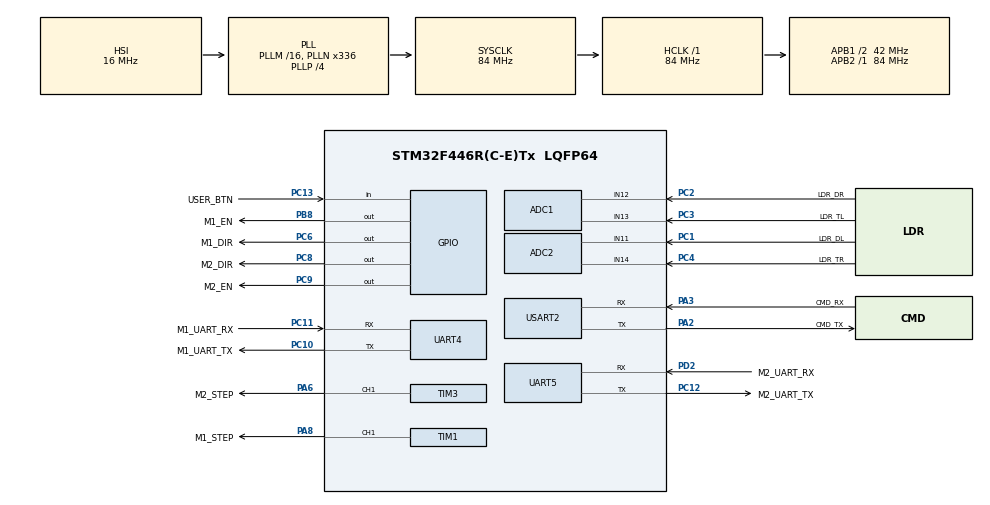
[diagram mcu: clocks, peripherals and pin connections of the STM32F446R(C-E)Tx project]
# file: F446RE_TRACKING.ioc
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ADC1.Channel-0\#ChannelRegularConversion=ADC_CHANNEL_12
ADC1.Channel-1\#ChannelRegularConversion=ADC_CHANNEL_13
ADC1.Channel-2\#ChannelRegularConversion=ADC_CHANNEL_12
ADC1.ContinuousConvMode=ENABLE
ADC1.DMAContinuousRequests=ENABLE
ADC1.EOCSelection=ADC_EOC_SEQ_CONV
ADC1.NbrOfConversion=2
ADC1.NbrOfConversionFlag=2
ADC1.Rank-0\#ChannelRegularConversion=2
ADC1.Rank-1\#ChannelRegularConversion=1
ADC1.Rank-2\#ChannelRegularConversion=2
ADC1.SamplingTime-0\#ChannelRegularConversion=ADC_SAMPLETIME_28CYCLES
ADC1.SamplingTime-1\#ChannelRegularConversion=ADC_SAMPLETIME_28CYCLES
ADC1.SamplingTime-2\#ChannelRegularConversion=ADC_SAMPLETIME_28CYCLES
ADC1.ScanConvMode=ENABLE
ADC1.master=1
ADC2.Channel-0\#ChannelRegularConversion=ADC_CHANNEL_14
ADC2.Channel-1\#ChannelRegularConversion=ADC_CHANNEL_11
ADC2.Channel-3\#ChannelRegularConversion=ADC_CHANNEL_11
ADC2.ContinuousConvMode=ENABLE
ADC2.DMAContinuousRequests=ENABLE
ADC2.EOCSelection=ADC_EOC_SEQ_CONV
ADC2.NbrOfConversion=2
ADC2.NbrOfConversionFlag=2
ADC2.Rank-0\#ChannelRegularConversion=1
ADC2.Rank-1\#ChannelRegularConversion=2
ADC2.Rank-3\#ChannelRegularConversion=2
ADC2.SamplingTime-0\#ChannelRegularConversion=ADC_SAMPLETIME_28CYCLES
ADC2.SamplingTime-1\#ChannelRegularConversion=ADC_SAMPLETIME_28CYCLES
ADC2.SamplingTime-3\#ChannelRegularConversion=ADC_SAMPLETIME_28CYCLES
Dma.ADC1.0.Direction=DMA_PERIPH_TO_MEMORY
Dma.ADC1.0.FIFOMode=DMA_FIFOMODE_DISABLE
Dma.ADC1.0.Instance=DMA2_Stream0
Dma.ADC1.0.MemDataAlignment=DMA_MDATAALIGN_HALFWORD
Dma.ADC1.0.MemInc=DMA_MINC_ENABLE
Dma.ADC1.0.Mode=DMA_CIRCULAR
Dma.ADC1.0.PeriphDataAlignment=DMA_PDATAALIGN_HALFWORD
Dma.ADC1.0.PeriphInc=DMA_PINC_DISABLE
Dma.ADC1.0.Priority=DMA_PRIORITY_LOW
Dma.ADC2.1.Direction=DMA_PERIPH_TO_MEMORY
Dma.ADC2.1.FIFOMode=DMA_FIFOMODE_DISABLE
Dma.ADC2.1.Instance=DMA2_Stream3
Dma.ADC2.1.MemDataAlignment=DMA_MDATAALIGN_HALFWORD
Dma.ADC2.1.MemInc=DMA_MINC_ENABLE
Dma.ADC2.1.Mode=DMA_CIRCULAR
Dma.ADC2.1.PeriphDataAlignment=DMA_PDATAALIGN_HALFWORD
Dma.ADC2.1.PeriphInc=DMA_PINC_DISABLE
Dma.ADC2.1.Priority=DMA_PRIORITY_LOW
Dma.Request0=ADC1
Dma.Request1=ADC2
Mcu.Family=STM32F4
Mcu.Name=STM32F446R(C-E)Tx
Mcu.Package=LQFP64
NVIC.ADC_IRQn=true\:0\:0\:false\:false\:true\:true\:true\:true
NVIC.DMA2_Stream0_IRQn=true\:0\:0\:false\:false\:true\:false\:true\:true
NVIC.DMA2_Stream3_IRQn=true\:0\:0\:false\:false\:true\:false\:true\:true
NVIC.PriorityGroup=NVIC_PRIORITYGROUP_0
NVIC.UART4_IRQn=true\:0\:0\:false\:false\:true\:true\:true\:true
NVIC.UART5_IRQn=true\:0\:0\:false\:false\:true\:true\:true\:true
PA13.GPIO_Label=TMS
PA13.Mode=Serial_Wire
PA13.Signal=SYS_JTMS-SWDIO
PA14.GPIO_Label=TCK
PA14.Mode=Serial_Wire
PA14.Signal=SYS_JTCK-SWCLK
PA2.GPIO_Label=CMD_TX
PA2.Mode=Asynchronous
PA2.Signal=USART2_TX
PA3.GPIO_Label=CMD_RX
PA3.Mode=Asynchronous
PA3.Signal=USART2_RX
PA6.GPIO_Label=M2_STEP
PA6.Signal=S_TIM3_CH1
PA8.GPIO_Label=M1_STEP
PA8.Signal=S_TIM1_CH1
PB3.GPIO_Label=SWO
PB3.Signal=SYS_JTDO-SWO
PB8.GPIO_Label=M1_EN
PB8.Signal=GPIO_Output
PC1.GPIO_Label=LDR_DL
PC1.Signal=ADCx_IN11
PC10.GPIO_Label=M1_UART_TX
PC10.Mode=Asynchronous
PC10.Signal=UART4_TX
PC11.GPIO_Label=M1_UART_RX
PC11.Mode=Asynchronous
PC11.Signal=UART4_RX
PC12.GPIO_Label=M2_UART_TX
PC12.Mode=Asynchronous
PC12.Signal=UART5_TX
PC13.GPIO_Label=USER_BTN
PC13.GPIO_PuPd=GPIO_PULLUP
PC13.Signal=GPIO_Input
PC14-OSC32_IN.Mode=LSE-External-Oscillator
PC14-OSC32_IN.Signal=RCC_OSC32_IN
PC15-OSC32_OUT.Mode=LSE-External-Oscillator
PC15-OSC32_OUT.Signal=RCC_OSC32_OUT
PC2.GPIO_Label=LDR_DR
PC2.Signal=ADCx_IN12
PC3.GPIO_Label=LDR_TL
PC3.Signal=ADCx_IN13
PC4.GPIO_Label=LDR_TR
PC4.Signal=ADCx_IN14
PC6.GPIO_Label=M1_DIR
PC6.Signal=GPIO_Output
PC8.GPIO_Label=M2_DIR
PC8.Signal=GPIO_Output
PC9.GPIO_Label=M2_EN
PC9.Signal=GPIO_Output
PD2.GPIO_Label=M2_UART_RX
PD2.Mode=Asynchronous
PD2.Signal=UART5_RX
PH0-OSC_IN.Mode=HSE-External-Oscillator
PH0-OSC_IN.Signal=RCC_OSC_IN
PH1-OSC_OUT.Mode=HSE-External-Oscillator
PH1-OSC_OUT.Signal=RCC_OSC_OUT
ProjectManager.HeapSize=0x200
ProjectManager.StackSize=0x400
ProjectManager.TargetToolchain=STM32CubeIDE
RCC.48MHZClocksFreq_Value=84000000
RCC.AHBFreq_Value=84000000
RCC.APB1CLKDivider=RCC_HCLK_DIV2
RCC.APB1Freq_Value=42000000
RCC.APB1TimFreq_Value=84000000
RCC.APB2Freq_Value=84000000
RCC.APB2TimFreq_Value=84000000
RCC.CortexFreq_Value=84000000
RCC.FLatency-AdvancedSettings=FLASH_LATENCY_2
RCC.HCLKFreq_Value=84000000
RCC.HSE_VALUE=8000000
RCC.HSI_VALUE=16000000
RCC.PLLN=336
RCC.PLLP=RCC_PLLP_DIV4
RCC.SYSCLKFreq_VALUE=84000000
RCC.SYSCLKSource=RCC_SYSCLKSOURCE_PLLCLK
RCC.USBFreq_Value=168000000
RCC.VCOOutputFreq_Value=336000000
SH.ADCx_IN11.0=ADC2_IN11,IN11
SH.ADCx_IN12.0=ADC1_IN12,IN12
SH.ADCx_IN13.0=ADC1_IN13,IN13
SH.ADCx_IN14.0=ADC2_IN14,IN14
SH.S_TIM1_CH1.0=TIM1_CH1,PWM Generation1 CH1
SH.S_TIM3_CH1.0=TIM3_CH1,PWM Generation1 CH1
TIM1.Channel-PWM\ Generation1\ CH1=TIM_CHANNEL_1
TIM1.Period=1000
TIM1.Prescaler=84-1
TIM1.Pulse-PWM\ Generation1\ CH1=500
TIM3.Channel-PWM\ Generation1\ CH1=TIM_CHANNEL_1
TIM3.Period=1000
TIM3.Prescaler=84-1
TIM3.Pulse-PWM\ Generation1\ CH1=500
UART4.VirtualMode=Asynchronous
UART5.VirtualMode=Asynchronous
USART2.VirtualMode=VM_ASYNC
board=NUCLEO-F446RE

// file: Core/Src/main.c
/* USER CODE BEGIN Header */
/**
  ******************************************************************************
  * @file           : main.c
  * @brief          : Main program body
  ******************************************************************************
  * @attention
  *
  * Copyright (c) 2026 STMicroelectronics.
  * All rights reserved.
  *
  * This software is licensed under terms that can be found in the LICENSE file
  * in the root directory of this software component.
  * If no LICENSE file comes with this software, it is provided AS-IS.
  *
  ******************************************************************************
  */
/* USER CODE END Header */
#include "main.h"

/* USER CODE BEGIN Includes */
#include "App/app_main.h"

/* USER CODE END Includes */

ADC_HandleTypeDef hadc1;
ADC_HandleTypeDef hadc2;
DMA_HandleTypeDef hdma_adc1;
DMA_HandleTypeDef hdma_adc2;

TIM_HandleTypeDef htim1;
TIM_HandleTypeDef htim3;

UART_HandleTypeDef huart4;
UART_HandleTypeDef huart5;
UART_HandleTypeDef huart2;

/* USER CODE BEGIN PV */
// 0323
/* USER CODE END PV */

void SystemClock_Config(void);
static void MX_GPIO_Init(void);
static void MX_DMA_Init(void);
static void MX_USART2_UART_Init(void);
static void MX_ADC1_Init(void);
static void MX_ADC2_Init(void);
static void MX_UART4_Init(void);
static void MX_UART5_Init(void);
static void MX_TIM1_Init(void);
static void MX_TIM3_Init(void);

int main(void)
{

  /* MCU Configuration--------------------------------------------------------*/

  /* Reset of all peripherals, Initializes the Flash interface and the Systick. */
  HAL_Init();

  /* Configure the system clock */
  SystemClock_Config();

  /* Initialize all configured peripherals */
  MX_GPIO_Init();
  MX_DMA_Init();
  MX_USART2_UART_Init();
  MX_ADC1_Init();
  MX_ADC2_Init();
  MX_UART4_Init();
  MX_UART5_Init();
  MX_TIM1_Init();
  MX_TIM3_Init();
  /* USER CODE BEGIN 2 */
  /* USART2 = ST-Link VCP (log/cmd) | TIM1=M1 step PWM | TIM3=M2 step PWM
   * UART4=M1 TMC2209 | UART5=M2 TMC2209 | TIM2/TIM5 (encoder) ?��使用 */
  AppMain_Init(&hadc1, &hadc2, &huart2, &htim1, &htim3, &huart4, &huart5);

  /* USER CODE END 2 */

  /* Infinite loop */
  while (1)
  {

    /* USER CODE BEGIN 3 */
    AppMain_Task();
  }
  /* USER CODE END 3 */
}

void SystemClock_Config(void)
{
  RCC_OscInitTypeDef RCC_OscInitStruct = {0};
  RCC_ClkInitTypeDef RCC_ClkInitStruct = {0};

  /** Configure the main internal regulator output voltage
  */
  __HAL_RCC_PWR_CLK_ENABLE();
  __HAL_PWR_VOLTAGESCALING_CONFIG(PWR_REGULATOR_VOLTAGE_SCALE3);

  /** Initializes the RCC Oscillators according to the specified parameters
  * in the RCC_OscInitTypeDef structure.
  */
  RCC_OscInitStruct.OscillatorType = RCC_OSCILLATORTYPE_HSI;
  RCC_OscInitStruct.HSIState = RCC_HSI_ON;
  RCC_OscInitStruct.HSICalibrationValue = RCC_HSICALIBRATION_DEFAULT;
  RCC_OscInitStruct.PLL.PLLState = RCC_PLL_ON;
  RCC_OscInitStruct.PLL.PLLSource = RCC_PLLSOURCE_HSI;
  RCC_OscInitStruct.PLL.PLLM = 16;
  RCC_OscInitStruct.PLL.PLLN = 336;
  RCC_OscInitStruct.PLL.PLLP = RCC_PLLP_DIV4;
  RCC_OscInitStruct.PLL.PLLQ = 2;
  RCC_OscInitStruct.PLL.PLLR = 2;
  if (HAL_RCC_OscConfig(&RCC_OscInitStruct) != HAL_OK)
  {
    Error_Handler();
  }

  /** Initializes the CPU, AHB and APB buses clocks
  */
  RCC_ClkInitStruct.ClockType = RCC_CLOCKTYPE_HCLK|RCC_CLOCKTYPE_SYSCLK
                              |RCC_CLOCKTYPE_PCLK1|RCC_CLOCKTYPE_PCLK2;
  RCC_ClkInitStruct.SYSCLKSource = RCC_SYSCLKSOURCE_PLLCLK;
  RCC_ClkInitStruct.AHBCLKDivider = RCC_SYSCLK_DIV1;
  RCC_ClkInitStruct.APB1CLKDivider = RCC_HCLK_DIV2;
  RCC_ClkInitStruct.APB2CLKDivider = RCC_HCLK_DIV1;

  if (HAL_RCC_ClockConfig(&RCC_ClkInitStruct, FLASH_LATENCY_2) != HAL_OK)
  {
    Error_Handler();
  }
}

static void MX_ADC1_Init(void)
{

  ADC_ChannelConfTypeDef sConfig = {0};

  /** Configure the global features of the ADC (Clock, Resolution, Data Alignment and number of conversion)
  */
  hadc1.Instance = ADC1;
  hadc1.Init.ClockPrescaler = ADC_CLOCK_SYNC_PCLK_DIV4;
  hadc1.Init.Resolution = ADC_RESOLUTION_12B;
  hadc1.Init.ScanConvMode = ENABLE;
  hadc1.Init.ContinuousConvMode = ENABLE;
  hadc1.Init.DiscontinuousConvMode = DISABLE;
  hadc1.Init.ExternalTrigConvEdge = ADC_EXTERNALTRIGCONVEDGE_NONE;
  hadc1.Init.ExternalTrigConv = ADC_SOFTWARE_START;
  hadc1.Init.DataAlign = ADC_DATAALIGN_RIGHT;
  hadc1.Init.NbrOfConversion = 2;
  hadc1.Init.DMAContinuousRequests = ENABLE;
  hadc1.Init.EOCSelection = ADC_EOC_SEQ_CONV;
  if (HAL_ADC_Init(&hadc1) != HAL_OK)
  {
    Error_Handler();
  }

  /** Configure for the selected ADC regular channel its corresponding rank in the sequencer and its sample time.
  */
  sConfig.Channel = ADC_CHANNEL_12;
  sConfig.Rank = 2;
  sConfig.SamplingTime = ADC_SAMPLETIME_28CYCLES;
  if (HAL_ADC_ConfigChannel(&hadc1, &sConfig) != HAL_OK)
  {
    Error_Handler();
  }

  /** Configure for the selected ADC regular channel its corresponding rank in the sequencer and its sample time.
  */
  sConfig.Channel = ADC_CHANNEL_13;
  sConfig.Rank = 1;
  if (HAL_ADC_ConfigChannel(&hadc1, &sConfig) != HAL_OK)
  {
    Error_Handler();
  }
  /* USER CODE BEGIN ADC1_Init 2 */
  /* CubeMX ??? rank ??��?? slot ??��?? Rank 2 ??? sample time ??��?? 3 cycles,
   * ?�裡??��?��?? 28 cycles,�? CH12/CH13 ?���? sample time �??��?? */
  sConfig.Channel      = ADC_CHANNEL_12;
  sConfig.Rank         = 2;
  sConfig.SamplingTime = ADC_SAMPLETIME_28CYCLES;
  if (HAL_ADC_ConfigChannel(&hadc1, &sConfig) != HAL_OK)
  {
    Error_Handler();
  }
  /* USER CODE END ADC1_Init 2 */

}

static void MX_ADC2_Init(void)
{

  ADC_ChannelConfTypeDef sConfig = {0};

  /** Configure the global features of the ADC (Clock, Resolution, Data Alignment and number of conversion)
  */
  hadc2.Instance = ADC2;
  hadc2.Init.ClockPrescaler = ADC_CLOCK_SYNC_PCLK_DIV4;
  hadc2.Init.Resolution = ADC_RESOLUTION_12B;
  hadc2.Init.ScanConvMode = ENABLE;
  hadc2.Init.ContinuousConvMode = ENABLE;
  hadc2.Init.DiscontinuousConvMode = DISABLE;
  hadc2.Init.ExternalTrigConvEdge = ADC_EXTERNALTRIGCONVEDGE_NONE;
  hadc2.Init.ExternalTrigConv = ADC_SOFTWARE_START;
  hadc2.Init.DataAlign = ADC_DATAALIGN_RIGHT;
  hadc2.Init.NbrOfConversion = 2;
  hadc2.Init.DMAContinuousRequests = ENABLE;
  hadc2.Init.EOCSelection = ADC_EOC_SEQ_CONV;
  if (HAL_ADC_Init(&hadc2) != HAL_OK)
  {
    Error_Handler();
  }

  /** Configure for the selected ADC regular channel its corresponding rank in the sequencer and its sample time.
  */
  sConfig.Channel = ADC_CHANNEL_14;
  sConfig.Rank = 1;
  sConfig.SamplingTime = ADC_SAMPLETIME_28CYCLES;
  if (HAL_ADC_ConfigChannel(&hadc2, &sConfig) != HAL_OK)
  {
    Error_Handler();
  }

  /** Configure for the selected ADC regular channel its corresponding rank in the sequencer and its sample time.
  */
  sConfig.Channel = ADC_CHANNEL_11;
  sConfig.Rank = 2;
  if (HAL_ADC_ConfigChannel(&hadc2, &sConfig) != HAL_OK)
  {
    Error_Handler();
  }
  /* USER CODE BEGIN ADC2_Init 2 */
  /* ??? ADC1,??? Rank 2 (CH11) ??? sample time ??��?? 28 cycles */
  sConfig.Channel      = ADC_CHANNEL_11;
  sConfig.Rank         = 2;
  sConfig.SamplingTime = ADC_SAMPLETIME_28CYCLES;
  if (HAL_ADC_ConfigChannel(&hadc2, &sConfig) != HAL_OK)
  {
    Error_Handler();
  }
  /* USER CODE END ADC2_Init 2 */

}

static void MX_TIM1_Init(void)
{

  TIM_MasterConfigTypeDef sMasterConfig = {0};
  TIM_OC_InitTypeDef sConfigOC = {0};
  TIM_BreakDeadTimeConfigTypeDef sBreakDeadTimeConfig = {0};

  htim1.Instance = TIM1;
  htim1.Init.Prescaler = 84-1;
  htim1.Init.CounterMode = TIM_COUNTERMODE_UP;
  htim1.Init.Period = 1000;
  htim1.Init.ClockDivision = TIM_CLOCKDIVISION_DIV1;
  htim1.Init.RepetitionCounter = 0;
  htim1.Init.AutoReloadPreload = TIM_AUTORELOAD_PRELOAD_DISABLE;
  if (HAL_TIM_PWM_Init(&htim1) != HAL_OK)
  {
    Error_Handler();
  }
  sMasterConfig.MasterOutputTrigger = TIM_TRGO_RESET;
  sMasterConfig.MasterSlaveMode = TIM_MASTERSLAVEMODE_DISABLE;
  if (HAL_TIMEx_MasterConfigSynchronization(&htim1, &sMasterConfig) != HAL_OK)
  {
    Error_Handler();
  }
  sConfigOC.OCMode = TIM_OCMODE_PWM1;
  sConfigOC.Pulse = 500;
  sConfigOC.OCPolarity = TIM_OCPOLARITY_HIGH;
  sConfigOC.OCNPolarity = TIM_OCNPOLARITY_HIGH;
  sConfigOC.OCFastMode = TIM_OCFAST_DISABLE;
  sConfigOC.OCIdleState = TIM_OCIDLESTATE_RESET;
  sConfigOC.OCNIdleState = TIM_OCNIDLESTATE_RESET;
  if (HAL_TIM_PWM_ConfigChannel(&htim1, &sConfigOC, TIM_CHANNEL_1) != HAL_OK)
  {
    Error_Handler();
  }
  sBreakDeadTimeConfig.OffStateRunMode = TIM_OSSR_DISABLE;
  sBreakDeadTimeConfig.OffStateIDLEMode = TIM_OSSI_DISABLE;
  sBreakDeadTimeConfig.LockLevel = TIM_LOCKLEVEL_OFF;
  sBreakDeadTimeConfig.DeadTime = 0;
  sBreakDeadTimeConfig.BreakState = TIM_BREAK_DISABLE;
  sBreakDeadTimeConfig.BreakPolarity = TIM_BREAKPOLARITY_HIGH;
  sBreakDeadTimeConfig.AutomaticOutput = TIM_AUTOMATICOUTPUT_DISABLE;
  if (HAL_TIMEx_ConfigBreakDeadTime(&htim1, &sBreakDeadTimeConfig) != HAL_OK)
  {
    Error_Handler();
  }
  HAL_TIM_MspPostInit(&htim1);

}

static void MX_TIM3_Init(void)
{

  TIM_MasterConfigTypeDef sMasterConfig = {0};
  TIM_OC_InitTypeDef sConfigOC = {0};

  htim3.Instance = TIM3;
  htim3.Init.Prescaler = 84-1;
  htim3.Init.CounterMode = TIM_COUNTERMODE_UP;
  htim3.Init.Period = 1000;
  htim3.Init.ClockDivision = TIM_CLOCKDIVISION_DIV1;
  htim3.Init.AutoReloadPreload = TIM_AUTORELOAD_PRELOAD_DISABLE;
  if (HAL_TIM_PWM_Init(&htim3) != HAL_OK)
  {
    Error_Handler();
  }
  sMasterConfig.MasterOutputTrigger = TIM_TRGO_RESET;
  sMasterConfig.MasterSlaveMode = TIM_MASTERSLAVEMODE_DISABLE;
  if (HAL_TIMEx_MasterConfigSynchronization(&htim3, &sMasterConfig) != HAL_OK)
  {
    Error_Handler();
  }
  sConfigOC.OCMode = TIM_OCMODE_PWM1;
  sConfigOC.Pulse = 500;
  sConfigOC.OCPolarity = TIM_OCPOLARITY_HIGH;
  sConfigOC.OCFastMode = TIM_OCFAST_DISABLE;
  if (HAL_TIM_PWM_ConfigChannel(&htim3, &sConfigOC, TIM_CHANNEL_1) != HAL_OK)
  {
    Error_Handler();
  }
  HAL_TIM_MspPostInit(&htim3);

}

static void MX_UART4_Init(void)
{

  huart4.Instance = UART4;
  huart4.Init.BaudRate = 115200;
  huart4.Init.WordLength = UART_WORDLENGTH_8B;
  huart4.Init.StopBits = UART_STOPBITS_1;
  huart4.Init.Parity = UART_PARITY_NONE;
  huart4.Init.Mode = UART_MODE_TX_RX;
  huart4.Init.HwFlowCtl = UART_HWCONTROL_NONE;
  huart4.Init.OverSampling = UART_OVERSAMPLING_16;
  if (HAL_UART_Init(&huart4) != HAL_OK)
  {
    Error_Handler();
  }

}

static void MX_UART5_Init(void)
{

  huart5.Instance = UART5;
  huart5.Init.BaudRate = 115200;
  huart5.Init.WordLength = UART_WORDLENGTH_8B;
  huart5.Init.StopBits = UART_STOPBITS_1;
  huart5.Init.Parity = UART_PARITY_NONE;
  huart5.Init.Mode = UART_MODE_TX_RX;
  huart5.Init.HwFlowCtl = UART_HWCONTROL_NONE;
  huart5.Init.OverSampling = UART_OVERSAMPLING_16;
  if (HAL_UART_Init(&huart5) != HAL_OK)
  {
    Error_Handler();
  }

}

static void MX_USART2_UART_Init(void)
{

  huart2.Instance = USART2;
  huart2.Init.BaudRate = 115200;
  huart2.Init.WordLength = UART_WORDLENGTH_8B;
  huart2.Init.StopBits = UART_STOPBITS_1;
  huart2.Init.Parity = UART_PARITY_NONE;
  huart2.Init.Mode = UART_MODE_TX_RX;
  huart2.Init.HwFlowCtl = UART_HWCONTROL_NONE;
  huart2.Init.OverSampling = UART_OVERSAMPLING_16;
  if (HAL_UART_Init(&huart2) != HAL_OK)
  {
    Error_Handler();
  }

}

static void MX_DMA_Init(void)
{

  /* DMA controller clock enable */
  __HAL_RCC_DMA2_CLK_ENABLE();

  /* DMA interrupt init */
  /* DMA2_Stream0_IRQn interrupt configuration */
  HAL_NVIC_SetPriority(DMA2_Stream0_IRQn, 0, 0);
  HAL_NVIC_EnableIRQ(DMA2_Stream0_IRQn);
  /* DMA2_Stream3_IRQn interrupt configuration */
  HAL_NVIC_SetPriority(DMA2_Stream3_IRQn, 0, 0);
  HAL_NVIC_EnableIRQ(DMA2_Stream3_IRQn);

}

static void MX_GPIO_Init(void)
{
  GPIO_InitTypeDef GPIO_InitStruct = {0};

  /* GPIO Ports Clock Enable */
  __HAL_RCC_GPIOC_CLK_ENABLE();
  __HAL_RCC_GPIOH_CLK_ENABLE();
  __HAL_RCC_GPIOA_CLK_ENABLE();
  __HAL_RCC_GPIOD_CLK_ENABLE();
  __HAL_RCC_GPIOB_CLK_ENABLE();

  /*Configure GPIO pin Output Level */
  HAL_GPIO_WritePin(GPIOC, GPIO_PIN_6|GPIO_PIN_8|GPIO_PIN_9, GPIO_PIN_RESET);

  /*Configure GPIO pin Output Level */
  HAL_GPIO_WritePin(GPIOB, GPIO_PIN_8, GPIO_PIN_RESET);

  /*Configure GPIO pin : PC13 */
  GPIO_InitStruct.Pin = GPIO_PIN_13;
  GPIO_InitStruct.Mode = GPIO_MODE_INPUT;
  GPIO_InitStruct.Pull = GPIO_PULLUP;
  HAL_GPIO_Init(GPIOC, &GPIO_InitStruct);

  /*Configure GPIO pins : PC6 PC8 PC9 */
  GPIO_InitStruct.Pin = GPIO_PIN_6|GPIO_PIN_8|GPIO_PIN_9;
  GPIO_InitStruct.Mode = GPIO_MODE_OUTPUT_PP;
  GPIO_InitStruct.Pull = GPIO_NOPULL;
  GPIO_InitStruct.Speed = GPIO_SPEED_FREQ_LOW;
  HAL_GPIO_Init(GPIOC, &GPIO_InitStruct);

  /*Configure GPIO pin : PB8 */
  GPIO_InitStruct.Pin = GPIO_PIN_8;
  GPIO_InitStruct.Mode = GPIO_MODE_OUTPUT_PP;
  GPIO_InitStruct.Pull = GPIO_NOPULL;
  GPIO_InitStruct.Speed = GPIO_SPEED_FREQ_LOW;
  HAL_GPIO_Init(GPIOB, &GPIO_InitStruct);

}

void Error_Handler(void)
{
  __disable_irq();
  while (1)
  {
  }
}
